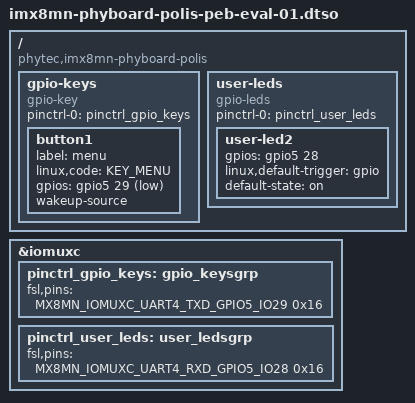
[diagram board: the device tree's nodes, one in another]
// SPDX-License-Identifier: GPL-2.0
/*
 * Copyright (C) 2020 PHYTEC Messtechnik GmbH
 * Author: Janine Hagemann <j.hagemann@phytec.de>
 */

/dts-v1/;
/plugin/;

#include <dt-bindings/gpio/gpio.h>
#include <dt-bindings/input/linux-event-codes.h>
#include "../imx8mn-pinfunc.h"

/ {
	compatible = "phytec,imx8mn-phyboard-polis";

	fragment@1 {
		target-path= "/";

		__overlay__ {

			gpio-keys {
				compatible = "gpio-key";
				pinctrl-names = "default";
				pinctrl-0 = <&pinctrl_gpio_keys>;

				button1 {
					label = "menu";
					linux,code = <KEY_MENU>;
					gpios = <&gpio5 29 GPIO_ACTIVE_LOW>;
					wakeup-source;
				};
			};

			user-leds {
				compatible = "gpio-leds";
				pinctrl-names = "default";
				pinctrl-0 = <&pinctrl_user_leds>;

				user-led2 {
					gpios = <&gpio5 28 GPIO_ACTIVE_HIGH>;
					linux,default-trigger = "gpio";
					default-state = "on";
				};
			};
		};
	};
};

&iomuxc {
	pinctrl_gpio_keys: gpio_keysgrp {
		fsl,pins = <
			MX8MN_IOMUXC_UART4_TXD_GPIO5_IO29	0x16
		>;
	};

	pinctrl_user_leds: user_ledsgrp {
		fsl,pins = <
			MX8MN_IOMUXC_UART4_RXD_GPIO5_IO28	0x16
		>;
	};
};
